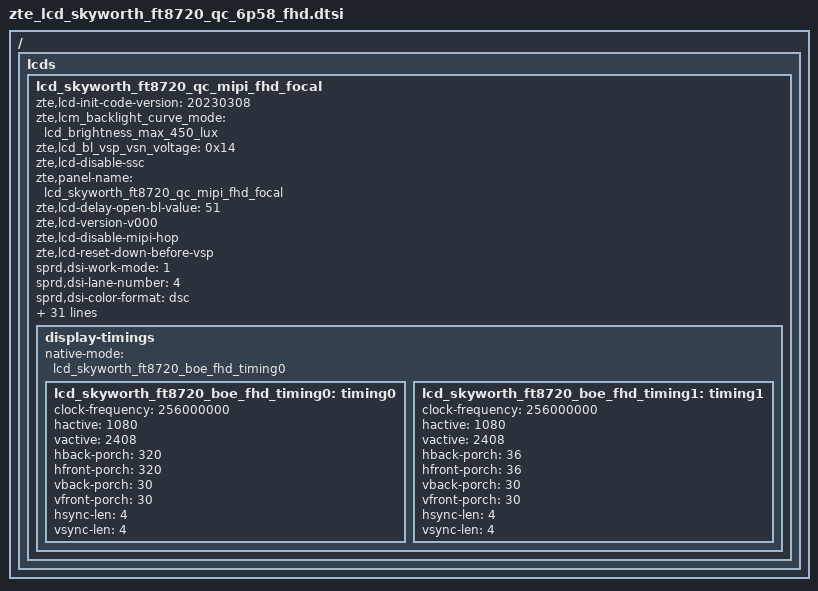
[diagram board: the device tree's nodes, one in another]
/ {
	fragment {
		target-path = "/";
		__overlay__ {
			lcds {
				lcd_skyworth_ft8720_qc_mipi_fhd_focal: lcd_skyworth_ft8720_qc_mipi_fhd_focal {
					zte,lcd-init-code-version = "20230308";

					zte,lcm_backlight_curve_mode = "lcd_brightness_max_450_lux";
					zte,lcd_bl_vsp_vsn_voltage = <0x14>;
					zte,lcd-disable-ssc;
					zte,panel-name = "lcd_skyworth_ft8720_qc_mipi_fhd_focal";
					zte,lcd-delay-open-bl-value = <51>;
					zte,lcd-version-v000;
					zte,lcd-disable-mipi-hop;
					zte,lcd-reset-down-before-vsp;

					sprd,dsi-work-mode = <1>;
					sprd,dsi-lane-number = <4>;
					sprd,dsi-color-format = "dsc";
					sprd,slice-width = <540>;
					sprd,slice-height = <8>;
					sprd,output-bpc = <8>;
					sprd,dsc-enable = <1>;
					sprd,dual-dsi-enable = <0>;
					zte,dsc-mode = <5>;

					sprd,phy-bit-clock = <819200>;
					sprd,phy-escape-clock = <20000>;/* kHz */

					sprd,width-mm = <68430>;
					sprd,height-mm = <152570>;

					sprd,esd-check-enable = <1>;/* 0:close , 1:open */
					sprd,esd-check-mode = <1>;/* 0:REG ,1:TE  */
					sprd,esd-check-period = <2000>;
					sprd,esd-check-register = <0x0A>;
					sprd,esd-check-value = <0x9C>;

					sprd,dphy-taget-val = <5>;

					sprd,reset-on-sequence = <1 5>, <0 10>, <1 35>;
					sprd,reset-off-sequence = <1 20>;

					sprd,use-dcs-write;
					sprd,initial-command = [
						29 00 00 02 00 00
						29 00 00 04 FF 87 20 01
						29 00 00 02 00 80
						29 00 00 03 FF 87 20
						29 00 00 02 00 A3
						29 00 00 03 B3 09 68
						29 00 00 02 00 80
						29 00 00 07 C0 00 61 00 30 00 10
						29 00 00 02 00 90
						29 00 00 07 C0 00 61 00 30 00 10
						29 00 00 02 00 A0
						29 00 00 07 C0 00 9E 00 30 00 10
						29 00 00 02 00 B0
						29 00 00 06 C0 00 BB 00 30 10
						29 00 00 02 00 60
						29 00 00 07 C0 00 9E 00 30 00 10
						29 00 00 02 00 70
						29 00 00 0D C0 00 C4 00 C8 0C 02 B6 00 00 15 00 EB
						29 00 00 02 00 A3
						29 00 00 07 C1 00 52 00 37 00 02
						29 00 00 02 00 80
						29 00 00 11 CE 01 81 FF FF 00 B4 00 C8 00 00 00 00 00 B8 00 C8
						29 00 00 02 00 90
						29 00 00 10 CE 00 A7 10 43 00 A7 80 FF FF 00 07 08 0F 0E 00
						29 00 00 02 00 A0
						29 00 00 04 CE 00 00 00
						29 00 00 02 00 B0
						29 00 00 04 CE 22 00 00
						29 00 00 02 00 D1
						29 00 00 08 CE 00 00 01 00 00 00 00
						29 00 00 02 00 E1
						29 00 00 0C CE 04 02 B6 02 B6 00 00 00 00 00 00
						29 00 00 02 00 F1
						29 00 00 0A CE 1F 15 00 01 28 00 EB 00 00
						29 00 00 02 00 B0
						29 00 00 05 CF 00 00 97 9B
						29 00 00 02 00 B5
						29 00 00 05 CF 04 05 FD 01
						29 00 00 02 00 C0
						29 00 00 05 CF 09 09 63 67
						29 00 00 02 00 C5
						29 00 00 05 CF 09 09 69 6D
						29 00 00 02 00 D1
						29 00 00 0D C1 0A A6 0E C8 19 67 07 E3 0B 11 13 04
						29 00 00 02 00 E1
						29 00 00 03 C1 0E C8
						29 00 00 02 00 E4
						29 00 00 0D CF 09 FC 09 FB 09 FB 09 FB 09 FB 09 FB
						29 00 00 02 00 80
						29 00 00 03 C1 00 00
						29 00 00 02 00 90
						29 00 00 02 C1 03
						29 00 00 02 00 F5
						29 00 00 02 CF 02
						29 00 00 02 00 F6
						29 00 00 02 CF 3C
						29 00 00 02 00 F1
						29 00 00 02 CF 3C
						29 00 00 02 00 F0
						29 00 00 02 C1 00
						29 00 00 02 00 CC
						29 00 00 02 C1 18
						29 00 00 02 00 91
						29 00 00 02 C4 88
						29 00 00 02 00 80
						29 00 00 02 C5 88
						29 00 00 02 00 80
						29 00 00 09 C2 81 00 02 8D 00 00 00 00
						29 00 00 02 00 90
						29 00 00 05 C2 80 00 04 8D
						29 00 00 02 00 A0
						29 00 00 10 C2 00 04 00 04 8D 01 05 00 04 8D 02 06 00 04 8D
						29 00 00 02 00 B0
						29 00 00 0B C2 03 04 00 04 8D 04 05 00 04 8D
						29 00 00 02 00 E0
						29 00 00 05 C2 44 44 40 00
						29 00 00 02 00 E8
						29 00 00 09 C2 0B 00 05 03 02 8A 00 00
						29 00 00 02 00 D0
						29 00 00 11 C3 35 00 00 00 35 00 00 00 35 00 00 00 00 00 00 00
						29 00 00 02 00 E0
						29 00 00 11 C3 35 00 00 00 35 00 00 00 35 00 00 00 00 00 00 00
						29 00 00 02 00 80
						29 00 00 11 CB 00 01 01 01 FD FD 00 FD 03 FE FD 01 00 00 00 03
						29 00 00 02 00 90
						29 00 00 11 CB 00 00 0F 00 0C 0C 00 00 FF 00 00 7F 00 00 00 FF
						29 00 00 02 00 A0
						29 00 00 09 CB 00 C0 00 00 00 00 00 00
						29 00 00 02 00 B0
						29 00 00 05 CB 40 D3 3D 00
						29 00 00 02 00 C0
						29 00 00 05 CB 40 00 C1 00
						29 00 00 02 00 D5
						29 00 00 0C CB 83 00 83 83 00 83 83 00 83 83 00
						29 00 00 02 00 E0
						29 00 00 0E CB 83 83 00 83 83 00 83 83 00 83 83 00 83
						29 00 00 02 00 80
						29 00 00 11 CC 20 1C 1E 1F 1C 12 02 0A 09 08 07 06 18 18 17 17
						29 00 00 02 00 90
						29 00 00 09 CC 16 16 18 18 17 17 16 16
						29 00 00 02 00 80
						29 00 00 11 CD 1C 1C 1E 1F 1C 12 02 0A 09 08 07 06 18 18 17 17
						29 00 00 02 00 90
						29 00 00 09 CD 16 16 18 18 17 17 16 16
						29 00 00 02 00 A0
						29 00 00 11 CC 20 1C 1E 1F 1C 02 12 09 0A 06 07 08 18 18 17 17
						29 00 00 02 00 B0
						29 00 00 09 CC 16 16 18 18 17 17 16 16
						29 00 00 02 00 A0
						29 00 00 11 CD 1C 1C 1E 1F 22 02 12 09 0A 06 07 08 18 18 17 17
						29 00 00 02 00 B0
						29 00 00 09 CD 16 16 18 18 17 17 16 16
						29 00 00 02 00 86
						29 00 00 07 C0 00 00 00 01 16 05
						29 00 00 02 00 96
						29 00 00 07 C0 00 00 00 01 16 05
						29 00 00 02 00 A6
						29 00 00 07 C0 00 00 00 01 29 05
						29 00 00 02 00 A3
						29 00 00 07 CE 00 00 00 01 16 05
						29 00 00 02 00 B3
						29 00 00 07 CE 00 00 00 01 16 05
						29 00 00 02 00 69
						29 00 00 04 C0 01 14 01
						29 00 00 02 00 82
						29 00 00 03 A7 10 00
						29 00 00 02 00 8D
						29 00 00 02 A7 01
						29 00 00 02 00 8F
						29 00 00 02 A7 01
						29 00 00 02 00 93
						29 00 00 02 C5 2D
						29 00 00 02 00 97
						29 00 00 02 C5 2D
						29 00 00 02 00 9A
						29 00 00 02 C5 19
						29 00 00 02 00 9C
						29 00 00 02 C5 19
						29 00 00 02 00 B6
						29 00 00 09 C5 14 14 0A 0A 14 14 0A 0A
						29 00 00 02 00 82
						29 00 00 02 F5 01
						29 00 00 02 00 93
						29 00 00 02 F5 01
						29 00 00 02 00 9B
						29 00 00 02 F5 49
						29 00 00 02 00 9D
						29 00 00 02 F5 49
						29 00 00 02 00 BE
						29 00 00 03 C5 F0 F0
						29 00 00 02 00 85
						29 00 00 02 A7 01
						29 00 00 02 00 DC
						29 00 00 02 C3 37
						29 00 00 02 00 8A
						29 00 00 02 F5 C7
						29 00 00 02 00 B1
						29 00 00 02 F5 1F
						29 00 00 02 00 B7
						29 00 00 02 F5 1F
						29 00 00 02 00 99
						29 00 00 02 CF 50
						29 00 00 02 00 9C
						29 00 00 02 F5 00
						29 00 00 02 00 9E
						29 00 00 02 F5 00
						29 00 00 02 00 B0
						29 00 00 07 C5 D0 4A 39 D0 4A 0E
						29 00 00 02 00 C2
						29 00 00 02 F5 42
						29 00 00 02 00 E8
						29 00 00 02 C0 40
						29 00 00 02 00 00
						29 00 00 03 D8 2F 2F
						29 00 00 02 00 00
						29 00 00 05 D9 28 28 28 28
						29 00 00 02 00 06
						29 00 00 04 D9 28 28 28
						29 00 00 02 00 00
						29 00 00 29 E1 0A 0A 0A 10 0A 19 20 26 30 BD 38 3E 43 48 1F 4D 54 5B 62 39 68 6F 76 7E 94 87 8C 92 99 6A A2 AC BA C3 2A CF E2 F2 FE E3
						29 00 00 02 00 30
						29 00 00 29 E1 0A 0A 0A 10 0A 19 20 26 30 BD 38 3E 43 48 1F 4D 54 5B 62 39 68 6F 76 7E 94 87 8C 92 99 6A A2 AC BA C3 2A CF E2 F2 FE E3
						29 00 00 02 00 60
						29 00 00 29 E1 0A 0A 0A 10 0A 19 20 26 30 BD 38 3E 43 48 1F 4D 54 5B 62 39 68 6F 76 7E 94 87 8C 92 99 6A A2 AC BA C3 2A CF E2 F2 FE E3
						29 00 00 02 00 90
						29 00 00 29 E1 0A 0A 0A 10 0A 19 20 26 30 BD 38 3E 43 48 1F 4D 54 5B 62 39 68 6F 76 7E 94 87 8C 92 99 6A A2 AC BA C3 2A CF E2 F2 FE E3
						29 00 00 02 00 C0
						29 00 00 29 E1 0A 0A 0A 10 0A 19 20 26 30 BD 38 3E 43 48 1F 4D 54 5B 62 39 68 6F 76 7E 94 87 8C 92 99 6A A2 AC BA C3 2A CF E2 F2 FE E3
						29 00 00 02 00 F0
						29 00 00 11 E1 0A 0A 0A 10 0A 19 20 26 30 BD 38 3E 43 48 1F 4D
						29 00 00 02 00 00
						29 00 00 19 E2 54 5B 62 39 68 6F 76 7E 94 87 8C 92 99 6A A2 AC BA C3 2A CF E2 F2 FE E3
						29 00 00 02 00 E0
						29 00 00 02 CF 34
						29 00 00 02 00 85
						29 00 00 02 A7 41
						29 00 00 02 00 B0
						29 00 00 02 B3 00
						29 00 00 02 00 83
						29 00 00 02 B0 63
						29 00 00 02 00 93
						29 00 00 02 C4 08
						29 00 00 02 00 80
						29 00 00 02 B3 22
						29 00 00 02 00 A1
						29 00 00 02 C5 40
						29 00 00 02 00 9D
						29 00 00 02 C5 44
						29 00 00 02 00 94
						29 00 00 02 C5 04
						29 00 00 02 00 98
						29 00 00 02 C5 24
						29 00 00 02 00 B0
						29 00 00 0F B4 00 08 02 00 00 BB 00 07 0D B7 0C B7 10 F0
						29 00 00 02 00 F6
						29 00 00 02 CF 3C/*60HZ in sprd,initial-command*/
						29 00 00 02 00 D2
						29 00 00 02 C0 01
						29 00 00 02 00 B0
						29 00 00 05 CF 00 00 A6 AA
						29 00 00 02 00 B5
						29 00 00 05 CF 05 05 0B 0F
						29 00 00 02 00 F0
						29 00 00 02 CF 01
						29 00 00 02 00 F1
						29 00 00 02 CF 5A
						29 00 00 02 00 00
						29 00 00 04 FF FF FF FF
						29 00 00 02 35 00
						05 78 00 01 11
						05 14 00 01 29
					];
					zte,initial-command-fps90 = [
						29 00 00 02 00 00
						29 00 00 04 FF 87 20 01
						29 00 00 02 00 80
						29 00 00 03 FF 87 20
						29 00 00 02 00 A3
						29 00 00 03 B3 09 68
						29 00 00 02 00 80
						29 00 00 07 C0 00 61 00 30 00 10
						29 00 00 02 00 90
						29 00 00 07 C0 00 61 00 30 00 10
						29 00 00 02 00 A0
						29 00 00 07 C0 00 9E 00 30 00 10
						29 00 00 02 00 B0
						29 00 00 06 C0 00 BB 00 30 10
						29 00 00 02 00 60
						29 00 00 07 C0 00 9E 00 30 00 10
						29 00 00 02 00 70
						29 00 00 0D C0 00 C4 00 C8 0C 02 B6 00 00 15 00 EB
						29 00 00 02 00 A3
						29 00 00 07 C1 00 52 00 37 00 02
						29 00 00 02 00 80
						29 00 00 11 CE 01 81 FF FF 00 B4 00 C8 00 00 00 00 00 B8 00 C8
						29 00 00 02 00 90
						29 00 00 10 CE 00 A7 10 43 00 A7 80 FF FF 00 07 08 0F 0E 00
						29 00 00 02 00 A0
						29 00 00 04 CE 00 00 00
						29 00 00 02 00 B0
						29 00 00 04 CE 22 00 00
						29 00 00 02 00 D1
						29 00 00 08 CE 00 00 01 00 00 00 00
						29 00 00 02 00 E1
						29 00 00 0C CE 04 02 B6 02 B6 00 00 00 00 00 00
						29 00 00 02 00 F1
						29 00 00 0A CE 1F 15 00 01 28 00 EB 00 00
						29 00 00 02 00 B0
						29 00 00 05 CF 00 00 97 9B
						29 00 00 02 00 B5
						29 00 00 05 CF 04 05 FD 01
						29 00 00 02 00 C0
						29 00 00 05 CF 09 09 63 67
						29 00 00 02 00 C5
						29 00 00 05 CF 09 09 69 6D
						29 00 00 02 00 D1
						29 00 00 0D C1 0A A6 0E C8 19 67 07 E3 0B 11 13 04
						29 00 00 02 00 E1
						29 00 00 03 C1 0E C8
						29 00 00 02 00 E4
						29 00 00 0D CF 09 FC 09 FB 09 FB 09 FB 09 FB 09 FB
						29 00 00 02 00 80
						29 00 00 03 C1 00 00
						29 00 00 02 00 90
						29 00 00 02 C1 03
						29 00 00 02 00 F5
						29 00 00 02 CF 02
						29 00 00 02 00 F6
						29 00 00 02 CF 3C
						29 00 00 02 00 F1
						29 00 00 02 CF 3C
						29 00 00 02 00 F0
						29 00 00 02 C1 00
						29 00 00 02 00 CC
						29 00 00 02 C1 18
						29 00 00 02 00 91
						29 00 00 02 C4 88
						29 00 00 02 00 80
						29 00 00 02 C5 88
						29 00 00 02 00 80
						29 00 00 09 C2 81 00 02 8D 00 00 00 00
						29 00 00 02 00 90
						29 00 00 05 C2 80 00 04 8D
						29 00 00 02 00 A0
						29 00 00 10 C2 00 04 00 04 8D 01 05 00 04 8D 02 06 00 04 8D
						29 00 00 02 00 B0
						29 00 00 0B C2 03 04 00 04 8D 04 05 00 04 8D
						29 00 00 02 00 E0
						29 00 00 05 C2 44 44 40 00
						29 00 00 02 00 E8
						29 00 00 09 C2 0B 00 05 03 02 8A 00 00
						29 00 00 02 00 D0
						29 00 00 11 C3 35 00 00 00 35 00 00 00 35 00 00 00 00 00 00 00
						29 00 00 02 00 E0
						29 00 00 11 C3 35 00 00 00 35 00 00 00 35 00 00 00 00 00 00 00
						29 00 00 02 00 80
						29 00 00 11 CB 00 01 01 01 FD FD 00 FD 03 FE FD 01 00 00 00 03
						29 00 00 02 00 90
						29 00 00 11 CB 00 00 0F 00 0C 0C 00 00 FF 00 00 7F 00 00 00 FF
						29 00 00 02 00 A0
						29 00 00 09 CB 00 C0 00 00 00 00 00 00
						29 00 00 02 00 B0
						29 00 00 05 CB 40 D3 3D 00
						29 00 00 02 00 C0
						29 00 00 05 CB 40 00 C1 00
						29 00 00 02 00 D5
						29 00 00 0C CB 83 00 83 83 00 83 83 00 83 83 00
						29 00 00 02 00 E0
						29 00 00 0E CB 83 83 00 83 83 00 83 83 00 83 83 00 83
						29 00 00 02 00 80
						29 00 00 11 CC 20 1C 1E 1F 1C 12 02 0A 09 08 07 06 18 18 17 17
						29 00 00 02 00 90
						29 00 00 09 CC 16 16 18 18 17 17 16 16
						29 00 00 02 00 80
						29 00 00 11 CD 1C 1C 1E 1F 1C 12 02 0A 09 08 07 06 18 18 17 17
						29 00 00 02 00 90
						29 00 00 09 CD 16 16 18 18 17 17 16 16
						29 00 00 02 00 A0
						29 00 00 11 CC 20 1C 1E 1F 1C 02 12 09 0A 06 07 08 18 18 17 17
						29 00 00 02 00 B0
						29 00 00 09 CC 16 16 18 18 17 17 16 16
						29 00 00 02 00 A0
						29 00 00 11 CD 1C 1C 1E 1F 22 02 12 09 0A 06 07 08 18 18 17 17
						29 00 00 02 00 B0
						29 00 00 09 CD 16 16 18 18 17 17 16 16
						29 00 00 02 00 86
						29 00 00 07 C0 00 00 00 01 16 05
						29 00 00 02 00 96
						29 00 00 07 C0 00 00 00 01 16 05
						29 00 00 02 00 A6
						29 00 00 07 C0 00 00 00 01 29 05
						29 00 00 02 00 A3
						29 00 00 07 CE 00 00 00 01 16 05
						29 00 00 02 00 B3
						29 00 00 07 CE 00 00 00 01 16 05
						29 00 00 02 00 69
						29 00 00 04 C0 01 14 01
						29 00 00 02 00 82
						29 00 00 03 A7 10 00
						29 00 00 02 00 8D
						29 00 00 02 A7 01
						29 00 00 02 00 8F
						29 00 00 02 A7 01
						29 00 00 02 00 93
						29 00 00 02 C5 2D
						29 00 00 02 00 97
						29 00 00 02 C5 2D
						29 00 00 02 00 9A
						29 00 00 02 C5 19
						29 00 00 02 00 9C
						29 00 00 02 C5 19
						29 00 00 02 00 B6
						29 00 00 09 C5 14 14 0A 0A 14 14 0A 0A
						29 00 00 02 00 82
						29 00 00 02 F5 01
						29 00 00 02 00 93
						29 00 00 02 F5 01
						29 00 00 02 00 9B
						29 00 00 02 F5 49
						29 00 00 02 00 9D
						29 00 00 02 F5 49
						29 00 00 02 00 BE
						29 00 00 03 C5 F0 F0
						29 00 00 02 00 85
						29 00 00 02 A7 01
						29 00 00 02 00 DC
						29 00 00 02 C3 37
						29 00 00 02 00 8A
						29 00 00 02 F5 C7
						29 00 00 02 00 B1
						29 00 00 02 F5 1F
						29 00 00 02 00 B7
						29 00 00 02 F5 1F
						29 00 00 02 00 99
						29 00 00 02 CF 50
						29 00 00 02 00 9C
						29 00 00 02 F5 00
						29 00 00 02 00 9E
						29 00 00 02 F5 00
						29 00 00 02 00 B0
						29 00 00 07 C5 D0 4A 39 D0 4A 0E
						29 00 00 02 00 C2
						29 00 00 02 F5 42
						29 00 00 02 00 E8
						29 00 00 02 C0 40
						29 00 00 02 00 00
						29 00 00 03 D8 2F 2F
						29 00 00 02 00 00
						29 00 00 05 D9 28 28 28 28
						29 00 00 02 00 06
						29 00 00 04 D9 28 28 28
						29 00 00 02 00 00
						29 00 00 29 E1 0A 0A 0A 10 0A 19 20 26 30 BD 38 3E 43 48 1F 4D 54 5B 62 39 68 6F 76 7E 94 87 8C 92 99 6A A2 AC BA C3 2A CF E2 F2 FE E3
						29 00 00 02 00 30
						29 00 00 29 E1 0A 0A 0A 10 0A 19 20 26 30 BD 38 3E 43 48 1F 4D 54 5B 62 39 68 6F 76 7E 94 87 8C 92 99 6A A2 AC BA C3 2A CF E2 F2 FE E3
						29 00 00 02 00 60
						29 00 00 29 E1 0A 0A 0A 10 0A 19 20 26 30 BD 38 3E 43 48 1F 4D 54 5B 62 39 68 6F 76 7E 94 87 8C 92 99 6A A2 AC BA C3 2A CF E2 F2 FE E3
						29 00 00 02 00 90
						29 00 00 29 E1 0A 0A 0A 10 0A 19 20 26 30 BD 38 3E 43 48 1F 4D 54 5B 62 39 68 6F 76 7E 94 87 8C 92 99 6A A2 AC BA C3 2A CF E2 F2 FE E3
						29 00 00 02 00 C0
						29 00 00 29 E1 0A 0A 0A 10 0A 19 20 26 30 BD 38 3E 43 48 1F 4D 54 5B 62 39 68 6F 76 7E 94 87 8C 92 99 6A A2 AC BA C3 2A CF E2 F2 FE E3
						29 00 00 02 00 F0
						29 00 00 11 E1 0A 0A 0A 10 0A 19 20 26 30 BD 38 3E 43 48 1F 4D
						29 00 00 02 00 00
						29 00 00 19 E2 54 5B 62 39 68 6F 76 7E 94 87 8C 92 99 6A A2 AC BA C3 2A CF E2 F2 FE E3
						29 00 00 02 00 E0
						29 00 00 02 CF 34
						29 00 00 02 00 85
						29 00 00 02 A7 41
						29 00 00 02 00 B0
						29 00 00 02 B3 00
						29 00 00 02 00 83
						29 00 00 02 B0 63
						29 00 00 02 00 93
						29 00 00 02 C4 08
						29 00 00 02 00 80
						29 00 00 02 B3 22
						29 00 00 02 00 A1
						29 00 00 02 C5 40
						29 00 00 02 00 9D
						29 00 00 02 C5 44
						29 00 00 02 00 94
						29 00 00 02 C5 04
						29 00 00 02 00 98
						29 00 00 02 C5 24
						29 00 00 02 00 B0
						29 00 00 0F B4 00 08 02 00 00 BB 00 07 0D B7 0C B7 10 F0
						29 00 00 02 00 F6
						29 00 00 02 CF 5A/*90HZ in zte,initial-command-fps90*/
						29 00 00 02 00 D2
						29 00 00 02 C0 00
						29 00 00 02 00 B0
						29 00 00 05 CF 00 00 97 9B
						29 00 00 02 00 B5
						29 00 00 05 CF 04 05 FD 01
						29 00 00 02 00 F0
						29 00 00 02 CF 01
						29 00 00 02 00 F1
						29 00 00 02 CF 78
						29 00 00 02 00 00
						29 00 00 04 FF FF FF FF
						29 00 00 02 35 00
						05 78 00 01 11
						05 14 00 01 29
					];

					sprd,sleep-in-command = [
						15 0A 00 01 28
						15 C8 00 01 10
						29 00 00 02 00 00
						29 00 00 04 FF 87 20 01
						29 00 00 02 00 80
						29 00 00 03 FF 87 20
						29 00 00 02 00 00
						29 14 00 05 F7 5A A5 95 27
						];
					sprd,sleep-out-command = [
						05 78 00 01 11
						05 32 00 01 29
						];
					zte,fps60-to-fps90 = [
						29 00 00 02 00 00
						29 00 00 04 FF 87 20 01
						/*29 00 00 02 00 F6
						29 00 00 02 CF 5A*/
						29 00 00 02 00 D2
						29 00 00 02 C0 00
						29 00 00 02 00 B0
						29 00 00 05 CF 00 00 97 9B
						29 00 00 02 00 B5
						29 00 00 05 CF 04 05 FD 01
						29 00 00 02 00 F0
						29 00 00 02 CF 01
						29 00 00 02 00 F1
						29 00 00 02 CF 78
						29 00 00 02 00 F6
						29 00 00 02 CF 5A
					];
					zte,fps90-to-fps60 = [
						29 00 00 02 00 00
						29 00 00 04 FF 87 20 01
						/*29 00 00 02 00 F6
						29 00 00 02 CF 3C*/
						29 00 00 02 00 D2
						29 00 00 02 C0 01
						29 00 00 02 00 B0
						29 00 00 05 CF 00 00 6A AA
						29 00 00 02 00 B5
						29 00 00 05 CF 05 05 0B 0F
						29 00 00 02 00 F0
						29 00 00 02 CF 01
						29 00 00 02 00 F1
						29 00 00 02 CF 5A
						29 00 00 02 00 F6
						29 00 00 02 CF 3C
					];
					display-timings {
						native-mode = <&lcd_skyworth_ft8720_boe_fhd_timing0>;
						lcd_skyworth_ft8720_boe_fhd_timing0: timing0 {
							clock-frequency = <256000000>;
							hactive = <1080>;
							vactive = <2408>;
							hback-porch = <320>;
							hfront-porch = <320>;
							vback-porch = <30>;
							vfront-porch = <30>;
							hsync-len = <4>;
							vsync-len = <4>;
						};
						lcd_skyworth_ft8720_boe_fhd_timing1: timing1 {
							clock-frequency = <256000000>;
							hactive = <1080>;
							vactive = <2408>;
							hback-porch = <36>;
							hfront-porch = <36>;
							vback-porch = <30>;
							vfront-porch = <30>;
							hsync-len = <4>;
							vsync-len = <4>;
						};
					};
				};
			};
		};
	};
};
